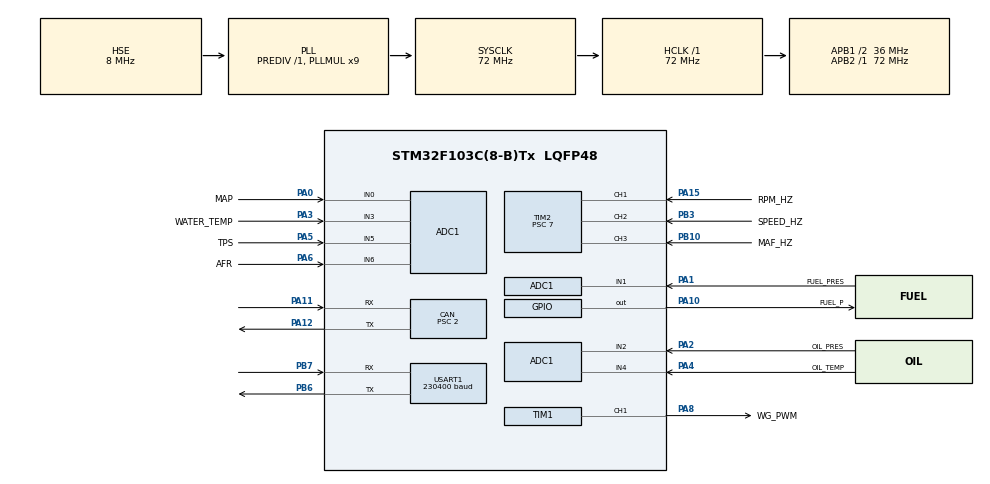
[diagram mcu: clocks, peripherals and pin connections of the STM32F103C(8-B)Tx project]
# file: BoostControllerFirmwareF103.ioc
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ADC1.Channel-0\#ChannelRegularConversion=ADC_CHANNEL_0
ADC1.Channel-1\#ChannelRegularConversion=ADC_CHANNEL_1
ADC1.Channel-2\#ChannelRegularConversion=ADC_CHANNEL_2
ADC1.Channel-3\#ChannelRegularConversion=ADC_CHANNEL_3
ADC1.Channel-4\#ChannelRegularConversion=ADC_CHANNEL_4
ADC1.Channel-5\#ChannelRegularConversion=ADC_CHANNEL_5
ADC1.Channel-6\#ChannelRegularConversion=ADC_CHANNEL_6
ADC1.ContinuousConvMode=DISABLE
ADC1.DiscontinuousConvMode=DISABLE
ADC1.NbrOfConversion=7
ADC1.NbrOfConversionFlag=1
ADC1.Rank-0\#ChannelRegularConversion=1
ADC1.Rank-1\#ChannelRegularConversion=2
ADC1.Rank-2\#ChannelRegularConversion=3
ADC1.Rank-3\#ChannelRegularConversion=4
ADC1.Rank-4\#ChannelRegularConversion=5
ADC1.Rank-5\#ChannelRegularConversion=6
ADC1.Rank-6\#ChannelRegularConversion=7
ADC1.SamplingTime-0\#ChannelRegularConversion=ADC_SAMPLETIME_239CYCLES_5
ADC1.SamplingTime-1\#ChannelRegularConversion=ADC_SAMPLETIME_239CYCLES_5
ADC1.SamplingTime-2\#ChannelRegularConversion=ADC_SAMPLETIME_239CYCLES_5
ADC1.SamplingTime-3\#ChannelRegularConversion=ADC_SAMPLETIME_239CYCLES_5
ADC1.SamplingTime-4\#ChannelRegularConversion=ADC_SAMPLETIME_239CYCLES_5
ADC1.SamplingTime-5\#ChannelRegularConversion=ADC_SAMPLETIME_239CYCLES_5
ADC1.SamplingTime-6\#ChannelRegularConversion=ADC_SAMPLETIME_239CYCLES_5
ADC1.master=1
CAN.BS1=CAN_BS1_12TQ
CAN.BS2=CAN_BS2_5TQ
CAN.CalculateBaudRate=1000000
CAN.CalculateTimeBit=1000
CAN.CalculateTimeQuantum=55.55555555555556
CAN.Prescaler=2
Dma.ADC1.0.Direction=DMA_PERIPH_TO_MEMORY
Dma.ADC1.0.Instance=DMA1_Channel1
Dma.ADC1.0.MemDataAlignment=DMA_MDATAALIGN_HALFWORD
Dma.ADC1.0.MemInc=DMA_MINC_ENABLE
Dma.ADC1.0.Mode=DMA_NORMAL
Dma.ADC1.0.PeriphDataAlignment=DMA_PDATAALIGN_HALFWORD
Dma.ADC1.0.PeriphInc=DMA_PINC_DISABLE
Dma.ADC1.0.Priority=DMA_PRIORITY_HIGH
Dma.Request0=ADC1
Dma.Request1=USART1_RX
Dma.USART1_RX.1.Direction=DMA_PERIPH_TO_MEMORY
Dma.USART1_RX.1.Instance=DMA1_Channel5
Dma.USART1_RX.1.MemDataAlignment=DMA_MDATAALIGN_BYTE
Dma.USART1_RX.1.MemInc=DMA_MINC_ENABLE
Dma.USART1_RX.1.Mode=DMA_CIRCULAR
Dma.USART1_RX.1.PeriphDataAlignment=DMA_PDATAALIGN_BYTE
Dma.USART1_RX.1.PeriphInc=DMA_PINC_DISABLE
Dma.USART1_RX.1.Priority=DMA_PRIORITY_LOW
Mcu.Family=STM32F1
Mcu.Name=STM32F103C(8-B)Tx
Mcu.Package=LQFP48
NVIC.ADC1_2_IRQn=true\:0\:0\:false\:false\:true\:true\:true\:true
NVIC.CAN1_RX1_IRQn=true\:0\:0\:false\:false\:true\:true\:true\:true
NVIC.CAN1_SCE_IRQn=true\:0\:0\:false\:false\:true\:true\:true\:true
NVIC.DMA1_Channel1_IRQn=true\:0\:0\:false\:false\:true\:false\:true\:true
NVIC.DMA1_Channel5_IRQn=true\:0\:0\:false\:false\:true\:false\:true\:true
NVIC.PriorityGroup=NVIC_PRIORITYGROUP_4
NVIC.TIM2_IRQn=true\:0\:0\:false\:false\:true\:true\:true\:true
NVIC.USB_LP_CAN1_RX0_IRQn=true\:0\:0\:false\:false\:true\:true\:true\:true
PA0-WKUP.GPIO_Label=MAP
PA0-WKUP.Signal=ADCx_IN0
PA1.GPIO_Label=FUEL_PRES
PA1.Signal=ADCx_IN1
PA10.GPIO_Label=FUEL_P
PA10.Signal=GPIO_Output
PA11.Mode=CAN_Activate
PA11.Signal=CAN_RX
PA12.Mode=CAN_Activate
PA12.Signal=CAN_TX
PA13.Mode=Serial_Wire
PA13.Signal=SYS_JTMS-SWDIO
PA14.Mode=Serial_Wire
PA14.Signal=SYS_JTCK-SWCLK
PA15.GPIO_Label=RPM_HZ
PA15.Signal=S_TIM2_CH1_ETR
PA2.GPIO_Label=OIL_PRES
PA2.Signal=ADCx_IN2
PA3.GPIO_Label=WATER_TEMP
PA3.Signal=ADCx_IN3
PA4.GPIO_Label=OIL_TEMP
PA4.Signal=ADCx_IN4
PA5.GPIO_Label=TPS
PA5.Signal=ADCx_IN5
PA6.GPIO_Label=AFR
PA6.Signal=ADCx_IN6
PA8.GPIO_Label=WG_PWM
PA8.Signal=S_TIM1_CH1
PB10.GPIO_Label=MAF_HZ
PB10.Signal=S_TIM2_CH3
PB3.GPIO_Label=SPEED_HZ
PB3.Signal=S_TIM2_CH2
PB6.Mode=Asynchronous
PB6.Signal=USART1_TX
PB7.Mode=Asynchronous
PB7.Signal=USART1_RX
PC14-OSC32_IN.Mode=LSE-External-Oscillator
PC14-OSC32_IN.Signal=RCC_OSC32_IN
PC15-OSC32_OUT.Mode=LSE-External-Oscillator
PC15-OSC32_OUT.Signal=RCC_OSC32_OUT
PD0-OSC_IN.Mode=HSE-External-Oscillator
PD0-OSC_IN.Signal=RCC_OSC_IN
PD1-OSC_OUT.Mode=HSE-External-Oscillator
PD1-OSC_OUT.Signal=RCC_OSC_OUT
ProjectManager.HeapSize=0x200
ProjectManager.StackSize=0x400
ProjectManager.TargetToolchain=Makefile
RCC.ADCPresc=RCC_ADCPCLK2_DIV6
RCC.AHBFreq_Value=72000000
RCC.APB1CLKDivider=RCC_HCLK_DIV2
RCC.APB1Freq_Value=36000000
RCC.APB1TimFreq_Value=72000000
RCC.APB2Freq_Value=72000000
RCC.APB2TimFreq_Value=72000000
RCC.HCLKFreq_Value=72000000
RCC.PLLMUL=RCC_PLL_MUL9
RCC.PLLSourceVirtual=RCC_PLLSOURCE_HSE
RCC.RTCClockSelection=RCC_RTCCLKSOURCE_LSE
RCC.SYSCLKFreq_VALUE=72000000
RCC.SYSCLKSource=RCC_SYSCLKSOURCE_PLLCLK
RCC.USBFreq_Value=72000000
SH.ADCx_IN0.0=ADC1_IN0,IN0
SH.ADCx_IN1.0=ADC1_IN1,IN1
SH.ADCx_IN2.0=ADC1_IN2,IN2
SH.ADCx_IN3.0=ADC1_IN3,IN3
SH.ADCx_IN4.0=ADC1_IN4,IN4
SH.ADCx_IN5.0=ADC1_IN5,IN5
SH.ADCx_IN6.0=ADC1_IN6,IN6
SH.S_TIM1_CH1.0=TIM1_CH1,PWM Generation1 CH1
SH.S_TIM2_CH1_ETR.0=TIM2_CH1,Input_Capture1_from_TI1
SH.S_TIM2_CH2.0=TIM2_CH2,Input_Capture2_from_TI2
SH.S_TIM2_CH3.0=TIM2_CH3,Input_Capture3_from_TI3
TIM1.Channel-PWM\ Generation1\ CH1=TIM_CHANNEL_1
TIM1.Prescaler=60
TIM2.AutoReloadPreload=TIM_AUTORELOAD_PRELOAD_ENABLE
TIM2.Channel-Input_Capture1_from_TI1=TIM_CHANNEL_1
TIM2.Channel-Input_Capture2_from_TI2=TIM_CHANNEL_2
TIM2.Channel-Input_Capture3_from_TI3=TIM_CHANNEL_3
TIM2.ICPolarity_CH1=TIM_INPUTCHANNELPOLARITY_RISING
TIM2.Prescaler=7
USART1.BaudRate=230400
USART1.VirtualMode=VM_ASYNC
VP_RTC_VS_RTC_Activate.Mode=RTC_Enabled
VP_TIM1_VS_ClockSourceINT.Mode=Internal
VP_TIM2_VS_ClockSourceINT.Mode=Internal
board=custom

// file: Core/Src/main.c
/* USER CODE BEGIN Header */
/**
  ******************************************************************************
  * @file           : main.c
  * @brief          : Main program body
  ******************************************************************************
  * @attention
  *
  * <h2><center>&copy; Copyright (c) 2021 STMicroelectronics.
  * All rights reserved.</center></h2>
  *
  * This software component is licensed by ST under BSD 3-Clause license,
  * the "License"; You may not use this file except in compliance with the
  * License. You may obtain a copy of the License at:
  *                        opensource.org/licenses/BSD-3-Clause
  *
  ******************************************************************************
  */
/* USER CODE END Header */
#include "main.h"

ADC_HandleTypeDef hadc1;
DMA_HandleTypeDef hdma_adc1;

CAN_HandleTypeDef hcan;

RTC_HandleTypeDef hrtc;

TIM_HandleTypeDef htim1;
TIM_HandleTypeDef htim2;

UART_HandleTypeDef huart1;
DMA_HandleTypeDef hdma_usart1_rx;

void SystemClock_Config(void);
static void MX_GPIO_Init(void);
static void MX_DMA_Init(void);
static void MX_ADC1_Init(void);
static void MX_CAN_Init(void);
static void MX_TIM1_Init(void);
static void MX_TIM2_Init(void);
static void MX_RTC_Init(void);
static void MX_USART1_UART_Init(void);

/* USER CODE BEGIN 0 */
void setup();
void loop();

/* USER CODE END 0 */

int main(void)
{

  /* MCU Configuration--------------------------------------------------------*/

  /* Reset of all peripherals, Initializes the Flash interface and the Systick. */
  HAL_Init();

  /* Configure the system clock */
  SystemClock_Config();

  /* Initialize all configured peripherals */
  MX_GPIO_Init();
  MX_DMA_Init();
  MX_ADC1_Init();
  MX_CAN_Init();
  MX_TIM1_Init();
  MX_TIM2_Init();
  MX_RTC_Init();
  MX_USART1_UART_Init();
  /* USER CODE BEGIN 2 */

  // Update tick frequency
  SystemCoreClockUpdate();

  // Start ADC clock

  // Calibrate The ADC On Power-Up For Better Accuracy
  HAL_ADCEx_Calibration_Start(&hadc1);

  HAL_TIM_IC_Start_IT(&htim2, TIM_CHANNEL_1);
  HAL_TIM_IC_Start_IT(&htim2, TIM_CHANNEL_2);
  HAL_TIM_IC_Start_IT(&htim2, TIM_CHANNEL_3);
  HAL_TIM_Base_Start_IT(&htim2);

  HAL_TIM_Base_Start(&htim1);

 	TIM1->CCR1 = 0;
 	HAL_TIM_PWM_Start(&htim1, TIM_CHANNEL_1);

  // Setup main app
  setup();

  /* USER CODE END 2 */

  /* Infinite loop */
  /* USER CODE BEGIN WHILE */
  while (1)
  {
    loop();
    /* USER CODE END WHILE */

  }
}

void SystemClock_Config(void)
{
  RCC_OscInitTypeDef RCC_OscInitStruct = {0};
  RCC_ClkInitTypeDef RCC_ClkInitStruct = {0};
  RCC_PeriphCLKInitTypeDef PeriphClkInit = {0};

  /** Initializes the RCC Oscillators according to the specified parameters
  * in the RCC_OscInitTypeDef structure.
  */
  RCC_OscInitStruct.OscillatorType = RCC_OSCILLATORTYPE_HSE|RCC_OSCILLATORTYPE_LSE;
  RCC_OscInitStruct.HSEState = RCC_HSE_ON;
  RCC_OscInitStruct.HSEPredivValue = RCC_HSE_PREDIV_DIV1;
  RCC_OscInitStruct.LSEState = RCC_LSE_ON;
  RCC_OscInitStruct.HSIState = RCC_HSI_ON;
  RCC_OscInitStruct.PLL.PLLState = RCC_PLL_ON;
  RCC_OscInitStruct.PLL.PLLSource = RCC_PLLSOURCE_HSE;
  RCC_OscInitStruct.PLL.PLLMUL = RCC_PLL_MUL9;
  if (HAL_RCC_OscConfig(&RCC_OscInitStruct) != HAL_OK)
  {
    Error_Handler();
  }

  /** Initializes the CPU, AHB and APB buses clocks
  */
  RCC_ClkInitStruct.ClockType = RCC_CLOCKTYPE_HCLK|RCC_CLOCKTYPE_SYSCLK
                              |RCC_CLOCKTYPE_PCLK1|RCC_CLOCKTYPE_PCLK2;
  RCC_ClkInitStruct.SYSCLKSource = RCC_SYSCLKSOURCE_PLLCLK;
  RCC_ClkInitStruct.AHBCLKDivider = RCC_SYSCLK_DIV1;
  RCC_ClkInitStruct.APB1CLKDivider = RCC_HCLK_DIV2;
  RCC_ClkInitStruct.APB2CLKDivider = RCC_HCLK_DIV1;

  if (HAL_RCC_ClockConfig(&RCC_ClkInitStruct, FLASH_LATENCY_2) != HAL_OK)
  {
    Error_Handler();
  }
  PeriphClkInit.PeriphClockSelection = RCC_PERIPHCLK_RTC|RCC_PERIPHCLK_ADC;
  PeriphClkInit.RTCClockSelection = RCC_RTCCLKSOURCE_LSE;
  PeriphClkInit.AdcClockSelection = RCC_ADCPCLK2_DIV6;
  if (HAL_RCCEx_PeriphCLKConfig(&PeriphClkInit) != HAL_OK)
  {
    Error_Handler();
  }
}

static void MX_ADC1_Init(void)
{

  ADC_ChannelConfTypeDef sConfig = {0};

  /** Common config
  */
  hadc1.Instance = ADC1;
  hadc1.Init.ScanConvMode = ADC_SCAN_ENABLE;
  hadc1.Init.ContinuousConvMode = DISABLE;
  hadc1.Init.DiscontinuousConvMode = DISABLE;
  hadc1.Init.ExternalTrigConv = ADC_SOFTWARE_START;
  hadc1.Init.DataAlign = ADC_DATAALIGN_RIGHT;
  hadc1.Init.NbrOfConversion = 7;
  if (HAL_ADC_Init(&hadc1) != HAL_OK)
  {
    Error_Handler();
  }

  /** Configure Regular Channel
  */
  sConfig.Channel = ADC_CHANNEL_0;
  sConfig.Rank = ADC_REGULAR_RANK_1;
  sConfig.SamplingTime = ADC_SAMPLETIME_239CYCLES_5;
  if (HAL_ADC_ConfigChannel(&hadc1, &sConfig) != HAL_OK)
  {
    Error_Handler();
  }

  /** Configure Regular Channel
  */
  sConfig.Channel = ADC_CHANNEL_1;
  sConfig.Rank = ADC_REGULAR_RANK_2;
  if (HAL_ADC_ConfigChannel(&hadc1, &sConfig) != HAL_OK)
  {
    Error_Handler();
  }

  /** Configure Regular Channel
  */
  sConfig.Channel = ADC_CHANNEL_2;
  sConfig.Rank = ADC_REGULAR_RANK_3;
  if (HAL_ADC_ConfigChannel(&hadc1, &sConfig) != HAL_OK)
  {
    Error_Handler();
  }

  /** Configure Regular Channel
  */
  sConfig.Channel = ADC_CHANNEL_3;
  sConfig.Rank = ADC_REGULAR_RANK_4;
  if (HAL_ADC_ConfigChannel(&hadc1, &sConfig) != HAL_OK)
  {
    Error_Handler();
  }

  /** Configure Regular Channel
  */
  sConfig.Channel = ADC_CHANNEL_4;
  sConfig.Rank = ADC_REGULAR_RANK_5;
  if (HAL_ADC_ConfigChannel(&hadc1, &sConfig) != HAL_OK)
  {
    Error_Handler();
  }

  /** Configure Regular Channel
  */
  sConfig.Channel = ADC_CHANNEL_5;
  sConfig.Rank = ADC_REGULAR_RANK_6;
  if (HAL_ADC_ConfigChannel(&hadc1, &sConfig) != HAL_OK)
  {
    Error_Handler();
  }

  /** Configure Regular Channel
  */
  sConfig.Channel = ADC_CHANNEL_6;
  sConfig.Rank = ADC_REGULAR_RANK_7;
  if (HAL_ADC_ConfigChannel(&hadc1, &sConfig) != HAL_OK)
  {
    Error_Handler();
  }

}

static void MX_CAN_Init(void)
{

  hcan.Instance = CAN1;
  hcan.Init.Prescaler = 2;
  hcan.Init.Mode = CAN_MODE_NORMAL;
  hcan.Init.SyncJumpWidth = CAN_SJW_1TQ;
  hcan.Init.TimeSeg1 = CAN_BS1_12TQ;
  hcan.Init.TimeSeg2 = CAN_BS2_5TQ;
  hcan.Init.TimeTriggeredMode = DISABLE;
  hcan.Init.AutoBusOff = DISABLE;
  hcan.Init.AutoWakeUp = DISABLE;
  hcan.Init.AutoRetransmission = DISABLE;
  hcan.Init.ReceiveFifoLocked = DISABLE;
  hcan.Init.TransmitFifoPriority = DISABLE;
  if (HAL_CAN_Init(&hcan) != HAL_OK)
  {
    Error_Handler();
  }

}

static void MX_RTC_Init(void)
{

  /** Initialize RTC Only
  */
  hrtc.Instance = RTC;
  hrtc.Init.AsynchPrediv = RTC_AUTO_1_SECOND;
  hrtc.Init.OutPut = RTC_OUTPUTSOURCE_ALARM;
  if (HAL_RTC_Init(&hrtc) != HAL_OK)
  {
    Error_Handler();
  }

}

static void MX_TIM1_Init(void)
{

  TIM_ClockConfigTypeDef sClockSourceConfig = {0};
  TIM_MasterConfigTypeDef sMasterConfig = {0};
  TIM_OC_InitTypeDef sConfigOC = {0};
  TIM_BreakDeadTimeConfigTypeDef sBreakDeadTimeConfig = {0};

  htim1.Instance = TIM1;
  htim1.Init.Prescaler = 60;
  htim1.Init.CounterMode = TIM_COUNTERMODE_UP;
  htim1.Init.Period = 65535;
  htim1.Init.ClockDivision = TIM_CLOCKDIVISION_DIV1;
  htim1.Init.RepetitionCounter = 0;
  htim1.Init.AutoReloadPreload = TIM_AUTORELOAD_PRELOAD_DISABLE;
  if (HAL_TIM_Base_Init(&htim1) != HAL_OK)
  {
    Error_Handler();
  }
  sClockSourceConfig.ClockSource = TIM_CLOCKSOURCE_INTERNAL;
  if (HAL_TIM_ConfigClockSource(&htim1, &sClockSourceConfig) != HAL_OK)
  {
    Error_Handler();
  }
  if (HAL_TIM_PWM_Init(&htim1) != HAL_OK)
  {
    Error_Handler();
  }
  sMasterConfig.MasterOutputTrigger = TIM_TRGO_RESET;
  sMasterConfig.MasterSlaveMode = TIM_MASTERSLAVEMODE_DISABLE;
  if (HAL_TIMEx_MasterConfigSynchronization(&htim1, &sMasterConfig) != HAL_OK)
  {
    Error_Handler();
  }
  sConfigOC.OCMode = TIM_OCMODE_PWM1;
  sConfigOC.Pulse = 0;
  sConfigOC.OCPolarity = TIM_OCPOLARITY_HIGH;
  sConfigOC.OCNPolarity = TIM_OCNPOLARITY_HIGH;
  sConfigOC.OCFastMode = TIM_OCFAST_DISABLE;
  sConfigOC.OCIdleState = TIM_OCIDLESTATE_RESET;
  sConfigOC.OCNIdleState = TIM_OCNIDLESTATE_RESET;
  if (HAL_TIM_PWM_ConfigChannel(&htim1, &sConfigOC, TIM_CHANNEL_1) != HAL_OK)
  {
    Error_Handler();
  }
  sBreakDeadTimeConfig.OffStateRunMode = TIM_OSSR_DISABLE;
  sBreakDeadTimeConfig.OffStateIDLEMode = TIM_OSSI_DISABLE;
  sBreakDeadTimeConfig.LockLevel = TIM_LOCKLEVEL_OFF;
  sBreakDeadTimeConfig.DeadTime = 0;
  sBreakDeadTimeConfig.BreakState = TIM_BREAK_DISABLE;
  sBreakDeadTimeConfig.BreakPolarity = TIM_BREAKPOLARITY_HIGH;
  sBreakDeadTimeConfig.AutomaticOutput = TIM_AUTOMATICOUTPUT_DISABLE;
  if (HAL_TIMEx_ConfigBreakDeadTime(&htim1, &sBreakDeadTimeConfig) != HAL_OK)
  {
    Error_Handler();
  }
  HAL_TIM_MspPostInit(&htim1);

}

static void MX_TIM2_Init(void)
{

  TIM_ClockConfigTypeDef sClockSourceConfig = {0};
  TIM_MasterConfigTypeDef sMasterConfig = {0};
  TIM_IC_InitTypeDef sConfigIC = {0};

  htim2.Instance = TIM2;
  htim2.Init.Prescaler = 7;
  htim2.Init.CounterMode = TIM_COUNTERMODE_UP;
  htim2.Init.Period = 65535;
  htim2.Init.ClockDivision = TIM_CLOCKDIVISION_DIV1;
  htim2.Init.AutoReloadPreload = TIM_AUTORELOAD_PRELOAD_ENABLE;
  if (HAL_TIM_Base_Init(&htim2) != HAL_OK)
  {
    Error_Handler();
  }
  sClockSourceConfig.ClockSource = TIM_CLOCKSOURCE_INTERNAL;
  if (HAL_TIM_ConfigClockSource(&htim2, &sClockSourceConfig) != HAL_OK)
  {
    Error_Handler();
  }
  if (HAL_TIM_IC_Init(&htim2) != HAL_OK)
  {
    Error_Handler();
  }
  sMasterConfig.MasterOutputTrigger = TIM_TRGO_RESET;
  sMasterConfig.MasterSlaveMode = TIM_MASTERSLAVEMODE_DISABLE;
  if (HAL_TIMEx_MasterConfigSynchronization(&htim2, &sMasterConfig) != HAL_OK)
  {
    Error_Handler();
  }
  sConfigIC.ICPolarity = TIM_INPUTCHANNELPOLARITY_RISING;
  sConfigIC.ICSelection = TIM_ICSELECTION_DIRECTTI;
  sConfigIC.ICPrescaler = TIM_ICPSC_DIV1;
  sConfigIC.ICFilter = 0;
  if (HAL_TIM_IC_ConfigChannel(&htim2, &sConfigIC, TIM_CHANNEL_1) != HAL_OK)
  {
    Error_Handler();
  }
  if (HAL_TIM_IC_ConfigChannel(&htim2, &sConfigIC, TIM_CHANNEL_2) != HAL_OK)
  {
    Error_Handler();
  }
  if (HAL_TIM_IC_ConfigChannel(&htim2, &sConfigIC, TIM_CHANNEL_3) != HAL_OK)
  {
    Error_Handler();
  }

}

static void MX_USART1_UART_Init(void)
{

  huart1.Instance = USART1;
  huart1.Init.BaudRate = 230400;
  huart1.Init.WordLength = UART_WORDLENGTH_8B;
  huart1.Init.StopBits = UART_STOPBITS_1;
  huart1.Init.Parity = UART_PARITY_NONE;
  huart1.Init.Mode = UART_MODE_TX_RX;
  huart1.Init.HwFlowCtl = UART_HWCONTROL_NONE;
  huart1.Init.OverSampling = UART_OVERSAMPLING_16;
  if (HAL_UART_Init(&huart1) != HAL_OK)
  {
    Error_Handler();
  }

}

static void MX_DMA_Init(void)
{

  /* DMA controller clock enable */
  __HAL_RCC_DMA1_CLK_ENABLE();

  /* DMA interrupt init */
  /* DMA1_Channel1_IRQn interrupt configuration */
  HAL_NVIC_SetPriority(DMA1_Channel1_IRQn, 0, 0);
  HAL_NVIC_EnableIRQ(DMA1_Channel1_IRQn);
  /* DMA1_Channel5_IRQn interrupt configuration */
  HAL_NVIC_SetPriority(DMA1_Channel5_IRQn, 0, 0);
  HAL_NVIC_EnableIRQ(DMA1_Channel5_IRQn);

}

static void MX_GPIO_Init(void)
{
  GPIO_InitTypeDef GPIO_InitStruct = {0};

  /* GPIO Ports Clock Enable */
  __HAL_RCC_GPIOC_CLK_ENABLE();
  __HAL_RCC_GPIOD_CLK_ENABLE();
  __HAL_RCC_GPIOA_CLK_ENABLE();
  __HAL_RCC_GPIOB_CLK_ENABLE();

  /*Configure GPIO pin Output Level */
  HAL_GPIO_WritePin(FUEL_P_GPIO_Port, FUEL_P_Pin, GPIO_PIN_RESET);

  /*Configure GPIO pin : FUEL_P_Pin */
  GPIO_InitStruct.Pin = FUEL_P_Pin;
  GPIO_InitStruct.Mode = GPIO_MODE_OUTPUT_PP;
  GPIO_InitStruct.Pull = GPIO_NOPULL;
  GPIO_InitStruct.Speed = GPIO_SPEED_FREQ_LOW;
  HAL_GPIO_Init(FUEL_P_GPIO_Port, &GPIO_InitStruct);

}

void Error_Handler(void)
{
  __disable_irq();
  while (1)
  {
  }
}
